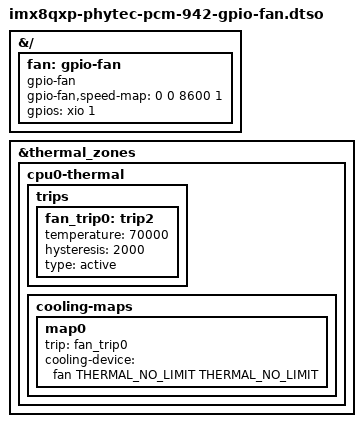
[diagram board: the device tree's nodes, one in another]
/*
 * SPDX-License-Identifier: GPL-2.0
 * Copyright (C) 2023 PHYTEC America, LLC - https://www.phytec.com
*/

/dts-v1/;
/plugin/;

#include <dt-bindings/gpio/gpio.h>
#include <dt-bindings/firmware/imx/rsrc.h>
#include <dt-bindings/thermal/thermal.h>

&{/} {
	fan: gpio-fan {
		compatible = "gpio-fan";
		gpio-fan,speed-map = <0 0 8600 1>;
		gpios = <&xio 1 GPIO_ACTIVE_HIGH>;
		#cooling-cells = <2>;
		status = "okay";
	};
};

&thermal_zones {
	cpu0-thermal {
		trips {
			fan_trip0: trip2 {
				temperature = <70000>;  /* millicelsius */
				hysteresis = <2000>;    /* millicelsius */
				type = "active";
			};
		};

		cooling-maps {
			map0 {
				trip = <&fan_trip0>;
				cooling-device = <&fan THERMAL_NO_LIMIT THERMAL_NO_LIMIT>;
			};
		};
	};
};
